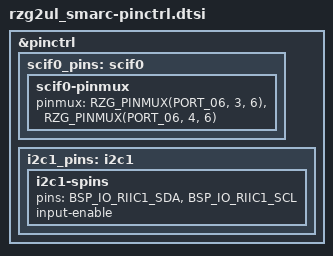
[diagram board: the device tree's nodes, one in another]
/*
 * Copyright (c) 2025 Renesas Electronics Corporation
 * SPDX-License-Identifier: Apache-2.0
 */

#include <zephyr/dt-bindings/gpio/gpio.h>
#include <zephyr/dt-bindings/pinctrl/renesas/pinctrl-rzg2-common.h>

&pinctrl {
	/omit-if-no-ref/ scif0_pins: scif0 {
		scif0-pinmux {
			pinmux = <RZG_PINMUX(PORT_06, 3, 6)>, /* RXD */
				 <RZG_PINMUX(PORT_06, 4, 6)>; /* TXD */
		};
	};

	/omit-if-no-ref/ i2c1_pins: i2c1 {
		i2c1-spins {
			pins = <BSP_IO_RIIC1_SDA>, <BSP_IO_RIIC1_SCL>;
			input-enable;
		};
	};
};
